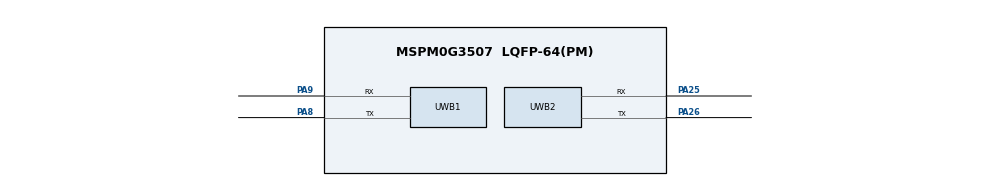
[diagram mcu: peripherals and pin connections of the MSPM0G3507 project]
/**
 * These arguments were used when this file was generated. They will be automatically applied on subsequent loads
 * via the GUI or CLI. Run CLI with '--help' for additional information on how to override these arguments.
 * @cliArgs --device "MSPM0G350X" --part "Default" --package "LQFP-64(PM)" --product "mspm0_sdk@2.10.00.04"
 * @v2CliArgs --device "MSPM0G3507" --package "LQFP-64(PM)" --product "mspm0_sdk@2.10.00.04"
 * @versions {"tool":"1.26.2+4477"}
 */

const SYSCTL = scripting.addModule("/ti/driverlib/SYSCTL");
const UART   = scripting.addModule("/ti/driverlib/UART", {}, false);
const Board  = scripting.addModule("/ti/driverlib/Board", {}, false);
const UWB1   = UART.addInstance();
const UWB2   = UART.addInstance();

const divider9       = system.clockTree["UDIV"];
divider9.divideValue = 2;

const gate7  = system.clockTree["MFCLKGATE"];
gate7.enable = true;

const multiplier2         = system.clockTree["PLL_QDIV"];
multiplier2.multiplyValue = 4;

const mux4       = system.clockTree["EXHFMUX"];
mux4.inputSelect = "EXHFMUX_XTAL";

const mux8       = system.clockTree["HSCLKMUX"];
mux8.inputSelect = "HSCLKMUX_SYSPLL0";

const mux12       = system.clockTree["SYSPLLMUX"];
mux12.inputSelect = "zSYSPLLMUX_HFCLK";

const pinFunction4        = system.clockTree["HFXT"];
pinFunction4.inputFreq    = 40;
pinFunction4.enable       = true;
pinFunction4.HFXTStartup  = 10;
pinFunction4.HFCLKMonitor = true;

SYSCTL.forceDefaultClkConfig = true;
SYSCTL.clockTreeEn           = true;

UWB1.$name                            = "UWB_CH1";
UWB1.targetBaudRate                   = 115200;
UWB1.enableFIFO                       = true;
UWB1.rxFifoThreshold                  = "DL_UART_RX_FIFO_LEVEL_ONE_ENTRY";
UWB1.enabledInterrupts                = ["RX"];
UWB1.peripheral.$assign               = "UART1";
UWB1.peripheral.rxPin.$assign         = "PA9";
UWB1.peripheral.txPin.$assign         = "PA8";
UWB1.txPinConfig.$name                = "UWB_CH1_TX";
UWB1.txPinConfig.direction            = scripting.forceWrite("OUTPUT");
UWB1.txPinConfig.hideOutputInversion  = scripting.forceWrite(false);
UWB1.txPinConfig.onlyInternalResistor = scripting.forceWrite(false);
UWB1.txPinConfig.passedPeripheralType = scripting.forceWrite("Digital");
UWB1.rxPinConfig.$name                = "UWB_CH1_RX";
UWB1.rxPinConfig.hideOutputInversion  = scripting.forceWrite(false);
UWB1.rxPinConfig.onlyInternalResistor = scripting.forceWrite(false);
UWB1.rxPinConfig.passedPeripheralType = scripting.forceWrite("Digital");

UWB2.$name                            = "UWB_CH2";
UWB2.targetBaudRate                   = 115200;
UWB2.enableFIFO                       = true;
UWB2.rxFifoThreshold                  = "DL_UART_RX_FIFO_LEVEL_ONE_ENTRY";
UWB2.enabledInterrupts                = ["RX"];
UWB2.peripheral.$assign               = "UART3";
UWB2.peripheral.rxPin.$assign         = "PA25";
UWB2.peripheral.txPin.$assign         = "PA26";
UWB2.txPinConfig.$name                = "UWB_CH2_TX";
UWB2.txPinConfig.direction            = scripting.forceWrite("OUTPUT");
UWB2.txPinConfig.hideOutputInversion  = scripting.forceWrite(false);
UWB2.txPinConfig.onlyInternalResistor = scripting.forceWrite(false);
UWB2.txPinConfig.passedPeripheralType = scripting.forceWrite("Digital");
UWB2.rxPinConfig.$name                = "UWB_CH2_RX";
UWB2.rxPinConfig.hideOutputInversion  = scripting.forceWrite(false);
UWB2.rxPinConfig.onlyInternalResistor = scripting.forceWrite(false);
UWB2.rxPinConfig.passedPeripheralType = scripting.forceWrite("Digital");

pinFunction4.peripheral.$suggestSolution           = "SYSCTL";
pinFunction4.peripheral.hfxInPin.$suggestSolution  = "PA5";
pinFunction4.peripheral.hfxOutPin.$suggestSolution = "PA6";
Board.peripheral.$suggestSolution                  = "DEBUGSS";
Board.peripheral.swclkPin.$suggestSolution         = "PA20";
Board.peripheral.swdioPin.$suggestSolution         = "PA19";
